# psoc6_04 register map
Vendor: Cypress Semiconductor; Series: PSoC6_04; File version: 1.0
CPU: CM4 r0p1, little endian, MPU, FPU, VTOR, 3 interrupt priority bits
Registers are 32-bit, read-write, reset 0x0 unless marked. A register's access mark holds for its fields unless they carry their own. Offsets are from the block's base; [hi:lo] are bit positions; lines under a group give offsets from that group; {n}, {i} and the like mark numbered series; 'fields as' and 'values as' point back to an identical list; <NAME> marks a mode.

## SMIF0 — Serial Memory Interface
Base 0x40420000
0x00 CTL reset 0x3000 — Control
  [31] ENABLED — IP enable: '0': Disabled. All non-retention registers are reset to their default value when the IP is disabled. When the IP is disabled, the XIP accesses produce AHB-Lite bus errors. '1': Enabled. Note: Before disabling the IP, SW should ensure that the IP is NOT busy (STATUS.BUSY is '0'), otherwise illegal interface transfers may occur.
    0=DISABLED (N/A); 1=ENABLED (N/A)
  [24] BLOCK — Specifies what happens for MMIO interface read accesses to an empty RX data FIFO or to a full TX format/data FIFO. Note: the FIFOs can only be accessed in MMIO_MODE. This field is not used for test controller accesses.
    0=BUS_ERROR (0': Generate an AHB-Lite bus error. This option is useful when SW decides to use polling on STATUS.TR_BUSY to determine if a interface transfer is no longer busy (transfer is completed). This option adds SW complexity, but limits the number of AHB-Lite wait states (and limits ISR latency).); 1=WAIT_STATES (1': Introduce wait states. This setting potentially locks up the AHB-Lite infrastructure and may increase the CPU interrupt latency.This option is useful when SW performs TX/RX data FIFO accesses immediately after a command is setup using the TX format FIFO. This option has low SW complexity, but may result in a significant number of AHB-Lite wait states (and may increase ISR latency).)
  [18:16] DESELECT_DELAY — Specifies the minimum duration of SPI deselection ('spi_select_out[]' is high/'1') in between SPI transfers: '0': 1 interface clock cycle. '1': 2 interface clock cycles. '2': 3 interface clock cycles. '3': 4 interface clock cycles. '4': 5 interface clock cycles. '5': 6 interface clock cycles. '6': 7 interface clock cycles. '7': 8 interface clock cycles. During SPI deselection, 'spi_select_out[]' are '1'/inactive, 'spi_data_out[]' are '1' and 'spi_clk_out' is '0'/inactive.
  [13:12] CLOCK_IF_RX_SEL — Specifies device interface receiver clock 'clk_if_rx' source. MISO data is captured on the rising edge of 'clk_if_rx'. '0': 'spi_clk_out' (internal clock) '1': !'spi_clk_out' (internal clock) '2': 'spi_clk_in' (feedback clock) '3': !'spi_clk_in' (feedback clock) Note: the device interface transmitter clock 'clk_if_tx' is fixed and is 'spi_clk_out' MOSI data is driven on the falling edge of 'clk_if_tx'.
  [0] XIP_MODE — Mode of operation. Note: this field should only be changed when the IP is disabled or when STATUS.BUSY is '0' and SW should not be executing from the XIP interface or MMIO interface.
    0=MMIO_MODE ('0': MMIO mode. Individual MMIO accesses to TX and RX FIFOs are used to generate a sequence of SPI transfers. This mode of operation allows for large flexibility in terms of the SPI transfers that can be generated.); 1=XIP_MODE (1': XIP mode. eXecute-In-Place mode: incoming read and write transfers over the AHB-Lite bus infrastructure are automatically translated in SPI transfers to read data from and write data to a device. This mode of operation allow for efficient device read and write operations. This mode is only supported in SPI_MODE.)
0x04 STATUS ro
  [31] BUSY — Cache, cryptography, XIP, device interface or any other logic busy in the IP: '0': not busy '1': busy When BUSY is '0', the IP can be safely disabled without: - the potential loss of transient write data. - the potential risk of aborting an inflight SPI device interface transfer. When BUSY is '0', the mode of operation (XIP_MODE or MMIO_MODE) can be safely changed.
0x44 TX_CMD_FIFO_STATUS ro — Transmitter command FIFO status
  [2:0] USED3 — Number of entries that are used in the TX command FIFO (available in both XIP_MODE and MMIO_MODE). Legal range: [0, 4].
0x50 TX_CMD_FIFO_WR wo — Transmitter command FIFO write
  [19:0] DATA20 — Command data. The higher two bits DATA[19:18] specify the specific command '0'/TX: A SPI transfer always start with a TX command FIFO entry of the 'TX' format. - DATA[17:16] specifies the width of the data transfer: - '0': 1 bit/cycle (single data transfer). - '1': 2 bits/cycle (dual data transfer). - '2': 4 bits/cycle (quad data transfer). - '3': 8 bits/cycle (octal data transfer). - DATA[15]: specifies whether this is the last TX Byte; i.e. whether the 'spi_select_out[3:0]' IO output signals are de-activated after the transfer. - DATA[11:8] specifies which of the four devices are selected. DATA[11:8] are directly mapped to 'spi_select_out[3:0]'. Two devices can be selected at the same time in dual-quad mode. - '0': device deselected - '1': device selected - DATA[7:0] specifies the transmitted Byte. '1'/TX_COUNT: The 'TX_COUNT' command relies on the TX data FIFO to provide the transmitted bytes. The 'TX_COUNT' command is ALWAYS considered to be the last command of a SPI data transfers. - DATA[17:16] specifies the width of the transfer. - DATA[15:0] specifies the number of to be transmitted Bytes (minus 1) from the TX data FIFO. '2'/RX_COUNT: The 'RX_COUNT' command relies on the RX data FIFO to accept the received bytes. The 'RX_COUNT' command is ALWAYS considered to be the last command of a SPI data transfers. - DATA[17:16] specifies the width of the transfer. - DATA[15:0] specifies the number of to be transmitted Bytes (minus 1) to the RX data FIFO. '3'/DUMMY_COUNT: The 'DUMMY_COUNT' command conveys dummy cycles. Dummy cycles are used to implement a Turn-Around time in which the SPI master changes from a transmitter driving the data lines to a receiver receiving on the same data lines. The 'DUMMY_COUNT' command is ALWAYS considered to be NOT the last command of a SPI data transfers; i.e. it needs to be followed by another command. - DATA[15:0] specifies the number of dummy cycles (minus 1). In dummy cycles, the data lines are not driven.
0x80 TX_DATA_FIFO_CTL — Transmitter data FIFO control
  [2:0] TRIGGER_LEVEL — Determines when the TX data FIFO 'tr_tx_req' trigger is activated (trigger activation requires MMIO_MODE, the trigger is NOT activated in XIP_MODE): - Trigger is active when TX_DATA_FIFO_STATUS.USED <= TRIGGER_LEVEL.
0x84 TX_DATA_FIFO_STATUS ro — Transmitter data FIFO status
  [3:0] USED4 — Number of entries that are used in the TX data FIFO (available in both XIP_MODE and MMIO_MODE). Legal range: [0, 8].
0x90 TX_DATA_FIFO_WR1 wo — Transmitter data FIFO write
  [7:0] DATA0 — TX data (written to TX data FIFO).
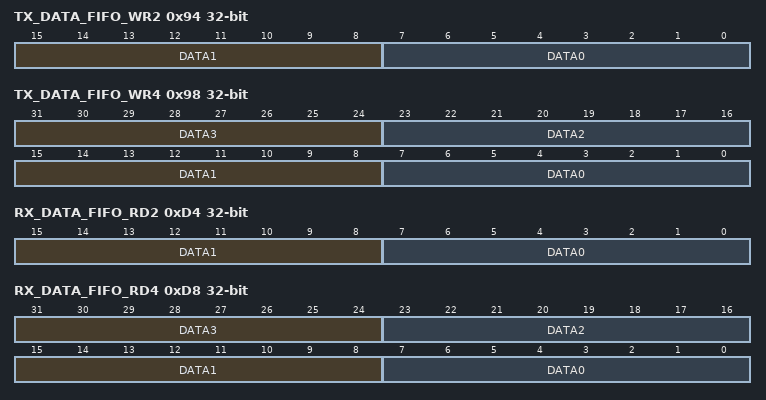
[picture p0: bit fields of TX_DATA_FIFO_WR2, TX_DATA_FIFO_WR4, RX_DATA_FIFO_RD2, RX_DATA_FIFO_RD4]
0x94 TX_DATA_FIFO_WR2 wo — Transmitter data FIFO write
  [15:8] DATA1 — TX data (written to TX data FIFO, second byte).
  [7:0] DATA0 — TX data (written to TX data FIFO, first byte).
0x98 TX_DATA_FIFO_WR4 wo — Transmitter data FIFO write
  [31:24] DATA3 — TX data (written to TX data FIFO, fourth byte).
  [23:16] DATA2 — TX data (written to TX data FIFO, third byte).
  [15:8] DATA1 — TX data (written to TX data FIFO, second byte).
  [7:0] DATA0 — TX data (written to TX data FIFO, first byte).
0xC0 RX_DATA_FIFO_CTL — Receiver data FIFO control
  [2:0] TRIGGER_LEVEL — Determines when RX data FIFO 'tr_rx_req' trigger is activated (trigger activation requires MMIO_MODE, the trigger is NOT activated in XIP_MODE): - Trigger is active when RX_DATA_FIFO_STATUS.USED > TRIGGER_LEVEL.
0xC4 RX_DATA_FIFO_STATUS ro — Receiver data FIFO status
  [3:0] USED4 — Number of entries that are used in the RX data FIFO (available in both XIP_MODE and MMIO_MODE). Legal range: [0, 8].
0xD0 RX_DATA_FIFO_RD1 ro — Receiver data FIFO read
  [7:0] DATA0 — RX data (read from RX data FIFO).
0xD4 RX_DATA_FIFO_RD2 ro — Receiver data FIFO read
  [15:8] DATA1 — RX data (read from RX data FIFO, second byte).
  [7:0] DATA0 — RX data (read from RX data FIFO, first byte).
0xD8 RX_DATA_FIFO_RD4 ro — Receiver data FIFO read
  [31:24] DATA3 — RX data (read from RX data FIFO, fourth byte).
  [23:16] DATA2 — RX data (read from RX data FIFO, third byte).
  [15:8] DATA1 — RX data (read from RX data FIFO, second byte).
  [7:0] DATA0 — RX data (read from RX data FIFO, first byte).
0xE0 RX_DATA_FIFO_RD1_SILENT ro — Receiver data FIFO silent read
  [7:0] DATA0 — RX data (read from RX data FIFO).
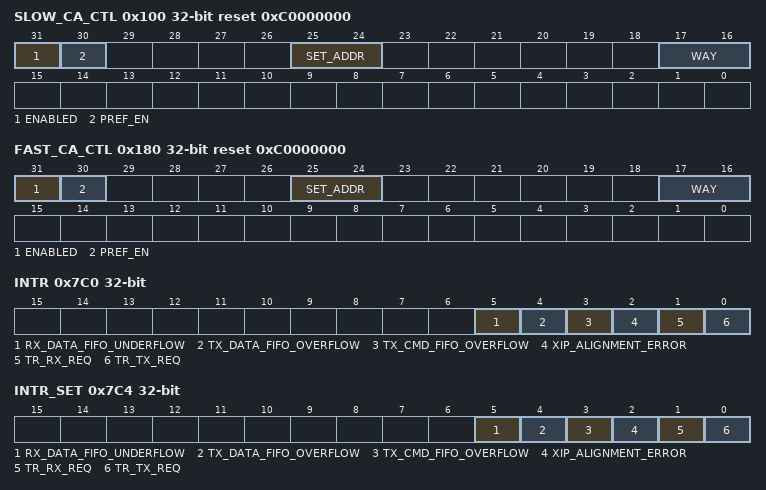
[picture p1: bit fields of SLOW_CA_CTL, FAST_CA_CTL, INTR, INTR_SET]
0x100 SLOW_CA_CTL reset 0xC0000000 — Slow cache control
  [31] ENABLED — Cache enable: '0': Disabled. '1': Enabled.
  [30] PREF_EN — Prefetch enable: '0': Disabled. '1': Enabled. Prefetching requires the cache to be enabled; i.e. ENABLED is '1'.
  [25:24] SET_ADDR — Specifies the cache set for which cache information is provided in SLOW_CA_STATUS0/1/2.
  [17:16] WAY — Specifies the cache way for which cache information is provided in SLOW_CA_STATUS0/1/2.
0x108 SLOW_CA_CMD — Slow cache command
  [0] INV — Cache and prefetch buffer invalidation. SW writes a '1' to clear the cache and prefetch buffer. The cache's LRU structure is also reset to its default state. Note, A write access will invalidate the prefetch buffer automatically in hardware. A write access should invalidate both fast and slow caches, by firmware. Note, firmware should invalidate the cache and prefetch buffer only when STATUS.BUSY is '0'.
0x180 FAST_CA_CTL reset 0xC0000000 — Fast cache control
  [31] ENABLED — See SLOW_CA_CTL.ENABLED.
  [30] PREF_EN — See SLOW_CA_CTL.PREF_EN.
  [25:24] SET_ADDR — See SLOW_CA_CTL.SET_ADDR.
  [17:16] WAY — See SLOW_CA_CTL.WAY.
0x188 FAST_CA_CMD — Fast cache command
  [0] INV — See SLOW_CA_CMD.INV.
0x200 CRYPTO_CMD — Cryptography Command
  [0] START — SW sets this field to '1' to start a AES-128 forward block cipher operation (on the address in CRYPTO_ADDR). HW sets this field to '0' to indicate that the operation has completed. Once completed, the result of the operation can be read from CRYPTO_RESULT0, ..., CRYPTO_RESULT3. The operation takes roughly 13 clk_hf clock cycles. Note: An operation can only be started in MMIO_MODE.
{0x220+4i} CRYPTO_INPUT{i} reset not defined (i=0..3) — Cryptography input {i}
  [31:0] INPUT — Four Bytes of the plaintext PT[{32i+31}:{32i}] = CRYPTO_INPUT{i}.INPUT[31:0].
{0x240+4i} CRYPTO_KEY{i} wo reset not defined (i=0..3) — Cryptography key {i}
  [31:0] KEY — Four Bytes of the key KEY[{32i+31}:{32i}] = CRYPTO_KEY{i}.KEY[31:0].
{0x260+4i} CRYPTO_OUTPUT{i} reset not defined (i=0..3) — Cryptography output {i}
  [31:0] OUTPUT — Four Bytes of the ciphertext CT[{32i+31}:{32i}] = CRYPTO_OUTPUT{i}.OUTPUT[31:0].
0x7C0 INTR — Interrupt register
  [5] RX_DATA_FIFO_UNDERFLOW — Activated in MMIO mode, on an AHB-Lite read transfer from the RX data FIFO (RX_DATA_FIFO_RD1, RX_DATA_FIFO_RD2, RX_DATA_FIFO_RD4) with not enough entries available. Only activated for NON test bus controller transfers.
  [4] TX_DATA_FIFO_OVERFLOW — Activated in MMIO mode, on an AHB-Lite write transfer to the TX data FIFO (TX_DATA_FIFO_WR1, TX_DATA_FIFO_WR2, TX_DATA_FIFO_WR4) with not enough free entries available.
  [3] TX_CMD_FIFO_OVERFLOW — Activated in MMIO mode, on an AHB-Lite write transfer to the TX command FIFO (TX_CMD_FIFO_WR) with not enough free entries available.
  [2] XIP_ALIGNMENT_ERROR — Activated in XIP mode, if: - The selected device's ADDR_CTL.DIV2 is '1' and the AHB-Lite bus transfer address is not a multiple of 2. - The selected device's ADDR_CTL.DIV2 is '1' and the XIP transfer request is NOT for a multiple of 2 Bytes. Note: In dual-quad SPI mode (ADDR_CTL.DIV is '1'), each memory device contributes a 4-bit nibble for read data or write data. This is only possible if the request address is a multiple of 2 and the number of requested Bytes is a multiple of 2.
  [1] TR_RX_REQ — Activated in MMIO mode, when a RX data FIFO trigger 'tr_rx_req' is activated.
  [0] TR_TX_REQ — Activated in MMIO mode, when a TX data FIFO trigger 'tr_tx_req' is activated.
0x7C4 INTR_SET — Interrupt set register
  [5] RX_DATA_FIFO_UNDERFLOW — Write with '1' to set corresponding bit in interrupt request register.
  [4] TX_DATA_FIFO_OVERFLOW — Write with '1' to set corresponding bit in interrupt request register.
  [3] TX_CMD_FIFO_OVERFLOW — Write with '1' to set corresponding bit in interrupt request register.
  [2] XIP_ALIGNMENT_ERROR — Write with '1' to set corresponding bit in interrupt request register.
  [1] TR_RX_REQ — Write with '1' to set corresponding bit in interrupt request register.
  [0] TR_TX_REQ — Write with '1' to set corresponding bit in interrupt request register.
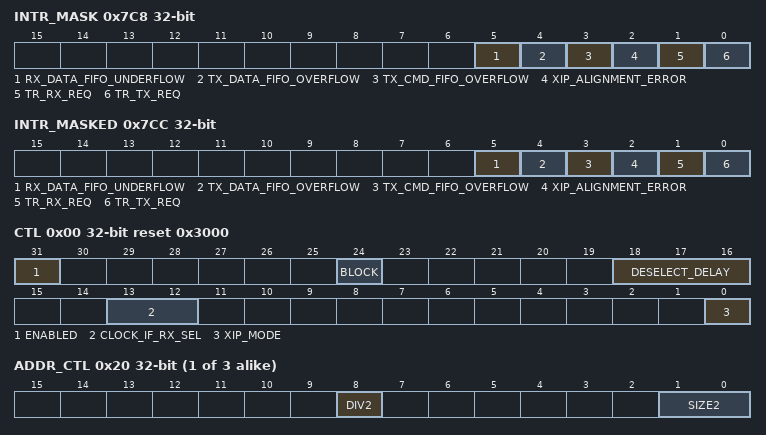
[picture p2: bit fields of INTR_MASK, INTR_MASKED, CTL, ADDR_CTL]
0x7C8 INTR_MASK — Interrupt mask register
  [5] RX_DATA_FIFO_UNDERFLOW — Mask bit for corresponding bit in interrupt request register.
  [4] TX_DATA_FIFO_OVERFLOW — Mask bit for corresponding bit in interrupt request register.
  [3] TX_CMD_FIFO_OVERFLOW — Mask bit for corresponding bit in interrupt request register.
  [2] XIP_ALIGNMENT_ERROR — Mask bit for corresponding bit in interrupt request register.
  [1] TR_RX_REQ — Mask bit for corresponding bit in interrupt request register.
  [0] TR_TX_REQ — Mask bit for corresponding bit in interrupt request register.
0x7CC INTR_MASKED ro — Interrupt masked register
  [5] RX_DATA_FIFO_UNDERFLOW — Logical and of corresponding request and mask bits.
  [4] TX_DATA_FIFO_OVERFLOW — Logical and of corresponding request and mask bits.
  [3] TX_CMD_FIFO_OVERFLOW — Logical and of corresponding request and mask bits.
  [2] XIP_ALIGNMENT_ERROR — Logical and of corresponding request and mask bits.
  [1] TR_RX_REQ — Logical and of corresponding request and mask bits.
  [0] TR_TX_REQ — Logical and of corresponding request and mask bits.
{0x800+0x80*i} DEVICE[{i}] (i=0..2) group — Device (only used in XIP mode)
  0x00 CTL — Control
    [31] ENABLED — Device enable: '0': Disabled. '1': Enabled.
    [17:16] DATA_SEL — Specifies the connection of the IP's data lines (spi_data[0], ..., spi_data[7]) to the device's data lines (SI/IO0, SO/IO1, IO2, IO3, IO4, IO5, IO6, IO7): '0': spi_data[0] = IO0, spi_data[1] = IO1, ..., spi_data[7] = IO7. This value is allowed for single, dual, quad, dual quad and octal SPI modes. This value must be used for the first device in dual quad SPI mode. This value must be used for octal SPI mode. '1': spi_data[2] = IO0, spi_data[3] = IO1. This value is only allowed for single and dual SPI modes. '2': spi_data[4] = IO0, spi_data[5] = IO1, ..., spi_data[7] = IO3. This value is only allowed for single, dual, quad and dual quad SPI modes. In dual quad SPI mode, this value must be used for the second device. '3': spi_data[6] = IO0, spi_data[7] = IO1. This value is only allowed for single and dual SPI modes.
    [8] CRYPTO_EN — Cryptography on read/write accesses: '0': disabled. '1': enabled.
    [0] WR_EN — Write enable: '0': write transfers are not allowed to this device. An attempt to write to this device results in an AHB-Lite bus error. '1': write transfers are allowed to this device.
  0x08 ADDR reset not defined — Device region base address
    [31:8] ADDR — Specifies the base address of the device region. If the device region is 2^m Bytes, ADDR MUST be a multiple of 2^m. In dual quad SPI data transfer, the two devices should have the same ADDR and MASK register settings. The device control information (ADDR_CTL, RD_CMD_CTL, etc.) are provided by the MMIO control registers of the device with the lowest index. The most significant bit fields are constants and set based on the SMIF_XIP_ADDR parameter. The most significant bits are identified on the SMIF_XIP_MASK parameter. E.g., if SMIF_XIP_MASK is 0xff00:0000 (16 MB XIP memory region), ADDR[31:24] = SMIF_XIP_ADDR[31:24].
  0x0C MASK reset not defined — Device region mask
    [31:8] MASK — Specifies the size of the device region. All '1' bits are used to compare the incoming transfer request address A[31:0] with the address as specified in ADDR.ADDR: Address A is in the device when (A[31:8] & MASK[31:8]) == ADDR.ADDR[31:8]. The most significant bit fields are constants and set to'1'. The most significant bits are identified on the SMIF_XIP_MASK parameter. E.g., if SMIF_XIP_MASK is 0xff00:0000 (16 MB XIP memory region), MASK[31:24] = 0xff. Note: a transfer request that is not in any device region results in an AHB-Lite bus error.
  0x20 ADDR_CTL — Address control
    [8] DIV2 — Specifies if the AHB-Lite bus transfer address is divided by 2 or not: '0': No divide by 2. '1': Divide by 2. This functionality is used for read and write operation in XIP, dual quad SPI mode; i.e. this DIV2 must be set to '1' in dual quad SPI mode. If the transfer request address is NOT a multiple of 2 or the requested number of Bytes is not a multiple of 2, the XIP_ALIGNMENT_ERROR interrupt cause is activated.
    [1:0] SIZE2 — Specifies the size of the XIP device address in Bytes: '0': 1 Byte address. '1': 2 Byte address. '2': 3 Byte address. '3': 4 Byte address. The lower significant address Bytes of the transfer request are used as XIP address to the external device. Note that for dual quad SPI data transfer, the transfer request address is divided by 2. Therefore, the transfer request address needs to be a multiple of 2. If the trasnfer requestaddress is NOT a multiple of 2, the XIP_ALIGNMENT_ERROR interrupt cause is activated.
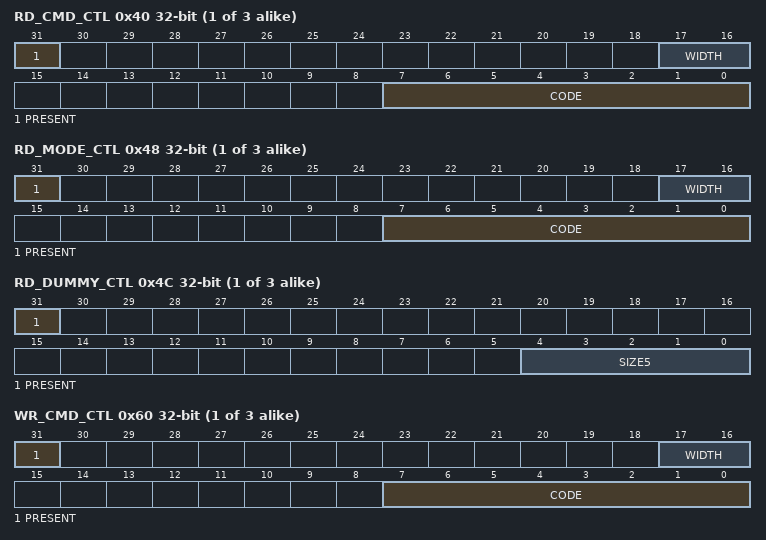
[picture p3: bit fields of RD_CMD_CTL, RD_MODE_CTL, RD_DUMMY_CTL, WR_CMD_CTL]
  0x40 RD_CMD_CTL — Read command control
    [31] PRESENT — Presence of command field: '0': not present '1': present
    [17:16] WIDTH — Width of data transfer: '0': 1 bit/cycle (single data transfer). '1': 2 bits/cycle (dual data transfer). '2': 4 bits/cycle (quad data transfer). '3': 8 bits/cycle (octal data transfer).
    [7:0] CODE — Command byte code.
  0x44 RD_ADDR_CTL — Read address control
    [17:16] WIDTH — Width of transfer.
  0x48 RD_MODE_CTL — Read mode control
    [31] PRESENT — Presence of mode field: '0': not present '1': present
    [17:16] WIDTH — Width of transfer.
    [7:0] CODE — Mode byte code.
  0x4C RD_DUMMY_CTL — Read dummy control
    [31] PRESENT — Presence of dummy cycles: '0': not present '1': present
    [4:0] SIZE5 — Number of dummy cycles (minus 1): '0': 1 cycles ... '31': 32 cycles. Note: this field specifies dummy cycles, not dummy Bytes!
  0x50 RD_DATA_CTL — Read data control
    [17:16] WIDTH — Width of transfer.
  0x60 WR_CMD_CTL — Write command control
    [31] PRESENT — Presence of command field: '0': not present '1': present
    [17:16] WIDTH — Width of transfer.
    [7:0] CODE — Command byte code.
  0x64 WR_ADDR_CTL — Write address control
    [17:16] WIDTH — Width of transfer.
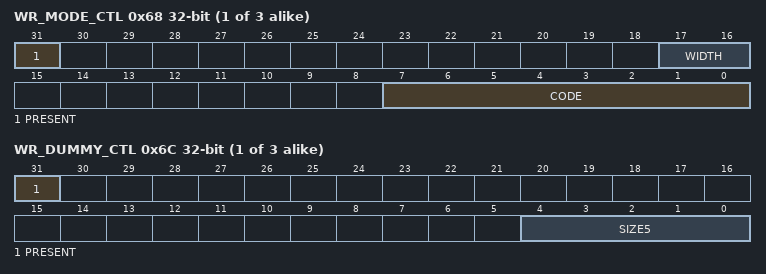
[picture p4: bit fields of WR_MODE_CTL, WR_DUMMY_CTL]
  0x68 WR_MODE_CTL — Write mode control
    fields as DEVICE[0].RD_MODE_CTL
  0x6C WR_DUMMY_CTL — Write dummy control
    [31] PRESENT — Presence of dummy cycles: '0': not present '1': present
    [4:0] SIZE5 — Number of dummy cycles (minus 1): '0': 1 cycles ... '31': 32 cycles.
  0x70 WR_DATA_CTL — Write data control
    [17:16] WIDTH — Width of transfer.

## Notices in the file
Copyright 2016-2020 Cypress Semiconductor Corporation
SPDX-License-Identifier: Apache-2.0
Licensed under the Apache License, Version 2.0 (the "License");
you may not use this file except in compliance with the License.
You may obtain a copy of the License at
http://www.apache.org/licenses/LICENSE-2.0
Unless required by applicable law or agreed to in writing, software
distributed under the License is distributed on an "AS IS" BASIS,
WITHOUT WARRANTIES OR CONDITIONS OF ANY KIND, either express or implied.
See the License for the specific language governing permissions and
limitations under the License.
